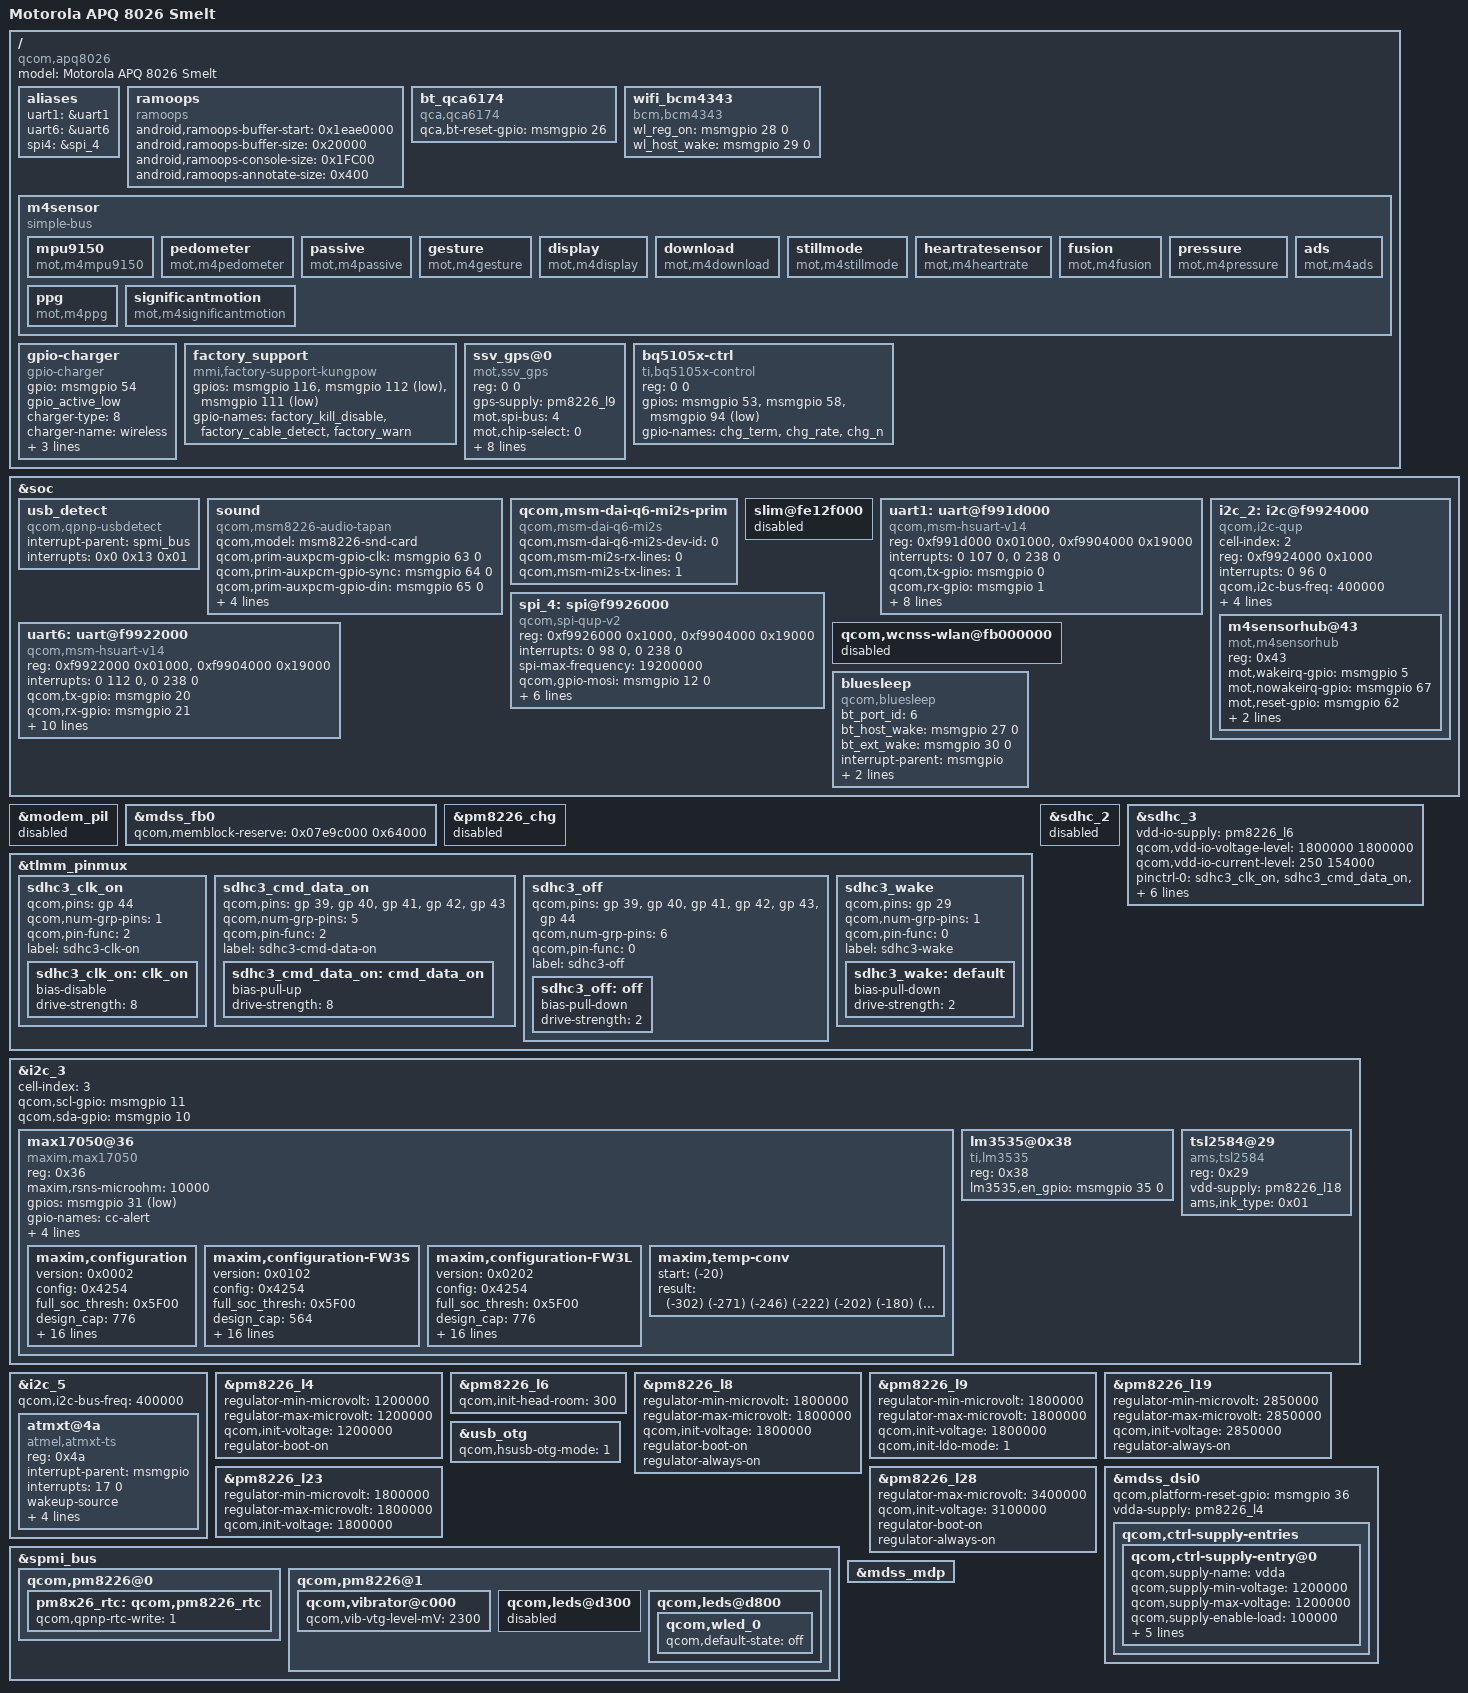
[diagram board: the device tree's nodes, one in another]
/* Copyright (c) 2014, The Linux Foundation. All rights reserved.
 *
 * This program is free software; you can redistribute it and/or modify
 * it under the terms of the GNU General Public License version 2 and
 * only version 2 as published by the Free Software Foundation.
 *
 * This program is distributed in the hope that it will be useful,
 * but WITHOUT ANY WARRANTY; without even the implied warranty of
 * MERCHANTABILITY or FITNESS FOR A PARTICULAR PURPOSE.  See the
 * GNU General Public License for more details.
 */

/memreserve/ 0x1eae0000 0x20000;

#include "qcom/apq8026-v2.dtsi"
#include "qcom/msm8226-w-memory.dtsi"
#include "qcom/msm8226-w-qseecom.dtsi"
#include "qcom/msm8226-w-sharedmem.dtsi"
#include "qcom/msm8226-720p-mtp.dtsi"
#include "apq8026-smelt-gpiomux.dtsi"

/ {
	model = "Motorola APQ 8026 Smelt";
	compatible = "qcom,apq8026", "qcom,msm8226", "qcom,mtp", "moto,smelt";

	aliases {
		/delete-property/ spi0;
		uart1 = &uart1;
		uart6 = &uart6;
		spi4 = &spi_4;
	};

	ramoops {
		compatible = "ramoops";
		status = "ok";

		android,ramoops-buffer-start = <0x1eae0000>;
		android,ramoops-buffer-size  = <0x20000>;
		android,ramoops-console-size = <0x1FC00>;
		android,ramoops-annotate-size = <0x400>;
	};

	bt_qca6174 {
		compatible = "qca,qca6174";
		qca,bt-reset-gpio = <&msmgpio 26 0>; /* BT_ENABLE */
	};

	wifi_bcm4343 {
		compatible = "bcm,bcm4343";
		wl_reg_on = <&msmgpio 28 0>;
		wl_host_wake = <&msmgpio 29 0>;
		status = "ok";
	};

	m4sensor {
		compatible = "simple-bus";

		mpu9150 {
			compatible = "mot,m4mpu9150";
		};
		pedometer {
			compatible = "mot,m4pedometer";
		};
		passive {
			compatible = "mot,m4passive";
		};
		gesture {
			compatible = "mot,m4gesture";
		};

		display {
			compatible = "mot,m4display";
		};
		download {
			compatible = "mot,m4download";
		};
		stillmode {
			compatible = "mot,m4stillmode";
		};

		heartratesensor {
			compatible = "mot,m4heartrate";
		};
		fusion {
			compatible = "mot,m4fusion";
		};
		pressure {
			compatible = "mot,m4pressure";
		};
		ads {
			compatible = "mot,m4ads";
		};
		ppg {
			compatible = "mot,m4ppg";
		};
		significantmotion {
			compatible = "mot,m4significantmotion";
		};
	};

	gpio-charger {
		compatible = "gpio-charger";
		gpio = <&msmgpio 54 0>;
		gpio_active_low;
		charger-type = <8>; /* POWER_SUPPLY_TYPE_WIRELESS */
		charger-name = "wireless";
		supplied_to = "max170xx_battery";
		switch-name = "dock";
		wakeup;
	};

	factory_support {
		compatible = "mmi,factory-support-kungpow";
		gpios = <&msmgpio 116 0x0>, /* GPIOF_OUT_INIT_LOW */
			<&msmgpio 112 0x1>, /* GPIOF_IN */
			<&msmgpio 111 0x1>; /* GPIOF_IN */
		gpio-names = "factory_kill_disable",
			     "factory_cable_detect",
			     "factory_warn";
	};

	ssv_gps@0 {
		compatible = "mot,ssv_gps";
		status = "ok";
		reg = <0 0>;
		gps-supply = <&pm8226_l9>;

		mot,spi-bus = <4>;
		mot,chip-select = <0>;
		mot,gps-spi-max-frequency = <6800000>;
		mot,rtc-clk = "sleep_clk";
		mot,modalias = "spidev";

		mot,boot-select-gpio = <&msmgpio 34 0x00>;
		mot,on-off-gpio      = <&msmgpio 37 0x00>;
		mot,irq-gpio         = <&msmgpio 46 0x00>;
		mot,reset-gpio       = <&msmgpio 48 0x00>;
		mot,host-wakeup-gpio = <&msmgpio 72 0x00>;
	};
	bq5105x-ctrl {
		reg = <0 0>;
		compatible = "ti,bq5105x-control";
		gpios = <&msmgpio 53 0x0>, /* WCHG_TERMINATE, GPIOF_OUT_INIT_LOW */
			<&msmgpio 58 0x0>, /* CHARGE_RATE, GPIOF_OUT_INIT_LOW */
		        <&msmgpio 94 0x1>; /* CHARGER_STARTB_1P8_N, GPIOF_IN */
		gpio-names = "chg_term",
			     "chg_rate",
			     "chg_n";
	};
};

&soc {
	usb_detect {
		compatible = "qcom,qpnp-usbdetect";
		interrupt-parent = <&spmi_bus>;
		interrupts = <0x0 0x13 0x01>;
		interrupt-names = "vbus_det_irq";
	};

	sound {
		compatible = "qcom,msm8226-audio-tapan";
		qcom,model = "msm8226-snd-card";
		qcom,prim-auxpcm-gpio-clk  = <&msmgpio 63 0>;
		qcom,prim-auxpcm-gpio-sync = <&msmgpio 64 0>;
		qcom,prim-auxpcm-gpio-din  = <&msmgpio 65 0>;
		qcom,prim-auxpcm-gpio-dout = <&msmgpio 66 0>;
		qcom,prim-auxpcm-gpio-set = "prim-gpio-prim";
		qcom,no-codec;
		qcom,mic-power-supply = <&pm8226_l23>;

		/delete-property/ qcom,audio-routing;
		/delete-property/ qcom,cdc-mclk-gpios;
		/delete-property/ qcom,cdc-vdd-spkr-gpios;
		/delete-property/ qcom,cdc-us-euro-gpios;
	};

	qcom,msm-dai-q6-mi2s-prim {
		compatible = "qcom,msm-dai-q6-mi2s";
		qcom,msm-dai-q6-mi2s-dev-id = <0>;
		qcom,msm-mi2s-rx-lines = <0>;
		qcom,msm-mi2s-tx-lines = <1>;
	};

	slim@fe12f000 {
		status = "disabled";
	};
	/delete-node/ sound-9302;

	/* BLSP1: UART */
	/delete-node/ spi@f9923000;
	uart1: uart@f991d000 { /* BLSP1 UART1 */
		compatible = "qcom,msm-hsuart-v14";
		reg = <0xf991d000 0x01000>,
		      <0xf9904000 0x19000>;
		reg-names = "core_mem", "bam_mem";
		interrupts = <0 107 0>, <0 238 0>;
		interrupt-names = "core_irq", "bam_irq";

		qcom,tx-gpio = <&msmgpio 0 0x00>;
		qcom,rx-gpio = <&msmgpio 1 0x00>;

		qcom,bam-tx-ep-pipe-index = <0>; /* BAM Consumer Pipe */
		qcom,bam-rx-ep-pipe-index = <1>; /* BAM Producer Pipe */
		qcom,msm-bus,name = "uart1";
		qcom,msm-bus,num-cases = <2>;
		qcom,msm-bus,num-paths = <1>;
		qcom,msm-obs;

		qcom,msm-bus,vectors-KBps =
			<86 512 0 0>,
			<86 512 500 800>;
	};

	/* BLSP2: I2C */
	i2c_2: i2c@f9924000 { /* BLSP-1 QUP-2 */
		cell-index = <2>;
		compatible = "qcom,i2c-qup";
		reg = <0xf9924000 0x1000>;
		#address-cells = <1>;
		#size-cells = <0>;
		reg-names = "qup_phys_addr";
		interrupts = <0 96 0>;
		interrupt-names = "qup_err_intr";
		qcom,i2c-bus-freq = <400000>;
		qcom,i2c-src-freq = <19200000>;
		qcom,scl-gpio = <&msmgpio 6 0>;
		qcom,sda-gpio = <&msmgpio 7 0>;
		qcom,master-id = <86>;
	};

	/* BLSP1-QUP3: [spi_4] (GPS) */
	/delete-node/ i2c@f9926000;
	spi_4: spi@f9926000 { /* BLSP1-QUP3 SPI4 */
		compatible = "qcom,spi-qup-v2";
		#address-cells = <1>;
		#size-cells = <0>;
		reg-names = "spi_physical", "spi_bam_physical";
		reg = <0xf9926000 0x1000>,
			<0xf9904000 0x19000>;
		interrupt-names = "spi_irq", "spi_bam_irq";
		interrupts = <0 98 0>, <0 238 0>;
		spi-max-frequency = <19200000>;
		qcom,gpio-mosi = <&msmgpio 12 0>;
		qcom,gpio-miso = <&msmgpio 13 0>;
		qcom,gpio-clk  = <&msmgpio 15 0>;
		qcom,gpio-cs0  = <&msmgpio 14 0>;
		qcom,infinite-mode = <0>;
		qcom,ver-reg-exists;
		qcom,master-id = <86>;
	};

	/* BLSP6: [uart] BT */
	uart6: uart@f9922000 { /* BLSP1 UART6 */
		compatible = "qcom,msm-hsuart-v14";
		reg = <0xf9922000 0x01000>,
		      <0xf9904000 0x19000>;
		reg-names = "core_mem", "bam_mem";
		interrupts = <0 112 0>, <0 238 0>;
		interrupt-names = "core_irq", "bam_irq";

		qcom,tx-gpio = <&msmgpio 20 0x00>;
		qcom,rx-gpio = <&msmgpio 21 0x00>;
		qcom,cts-gpio = <&msmgpio 22 0x00>;
		qcom,rfr-gpio = <&msmgpio 23 0x00>;

		qcom,bam-tx-ep-pipe-index = <10>; /* BAM Consumer Pipe */
		qcom,bam-rx-ep-pipe-index = <11>; /* BAM Producer Pipe */
		qcom,msm-bus,name = "uart6";
		qcom,msm-bus,num-cases = <2>;
		qcom,msm-bus,num-paths = <1>;
		qcom,msm-obs;

		qcom,msm-bus,vectors-KBps =
			<86 512 0 0>,
			<86 512 500 800>;
	};

	qcom,wcnss-wlan@fb000000 {
		status = "disabled";
	};

	bluesleep {
		compatible = "qcom,bluesleep";
		bt_port_id = <6>;
		bt_host_wake = <&msmgpio 27 0>;
		bt_ext_wake = <&msmgpio 30 0>;
		interrupt-parent = <&msmgpio>;
		interrupts = <27 0>;
		interrupt-names = "host_wake";
		tx-timer-interval = <1>;
	};

};

&modem_pil {
	status = "disabled";
	/delete-property/ linux,contiguous-region;
};

&mdss_fb0 {
	/* cont_splash memory*/
	qcom,memblock-reserve = <0x07e9c000 0x64000>;
};

&pm8226_chg {
	status = "disabled";
};

&tlmm_pinmux {
	sdhc3_clk_on {
		qcom,pins = <&gp 44>;
		qcom,num-grp-pins = <1>;
		qcom,pin-func = <2>;
		label = "sdhc3-clk-on";
		sdhc3_clk_on: clk_on {
			bias-disable;
			drive-strength = <8>;
		};
	};

	sdhc3_cmd_data_on {
		qcom,pins = <&gp 39 &gp 40 &gp 41 &gp 42 &gp 43>;
		qcom,num-grp-pins = <5>;
		qcom,pin-func = <2>;
		label = "sdhc3-cmd-data-on";
		sdhc3_cmd_data_on: cmd_data_on {
			bias-pull-up;
			drive-strength = <8>;
		};
	};

	sdhc3_off {
		qcom,pins = <&gp 39 &gp 40 &gp 41 &gp 42 &gp 43 &gp 44>;
		qcom,num-grp-pins = <6>;
		qcom,pin-func = <0>;
		label = "sdhc3-off";
		sdhc3_off: off {
			bias-pull-down;
			drive-strength = <2>;
		};
	};

	sdhc3_wake {
		qcom,pins = <&gp 29>;
		qcom,num-grp-pins = <1>;
		qcom,pin-func = <0>;
		label = "sdhc3-wake";
		sdhc3_wake: default {
			bias-pull-down;
			drive-strength = <2>;
		};
	};
};

&sdhc_2 {
	status = "disabled";
};

&sdhc_3 {
	vdd-io-supply = <&pm8226_l6>;
	qcom,vdd-io-voltage-level = <1800000 1800000>;
	qcom,vdd-io-current-level = <250 154000>;

	pinctrl-names = "active", "sleep";
	pinctrl-0 = <&sdhc3_clk_on &sdhc3_cmd_data_on &sdhc3_wake>;
	pinctrl-1 = <&sdhc3_off &sdhc3_wake>;

	interrupt-map = <0 &intc 0 127 0
			 1 &intc 0 224 0>;
	interrupt-names = "hc_irq", "pwr_irq";

	qcom,nonremovable;
	qcom,ignore_voltage_mismatch;
	qcom,no-uhs;
	status = "ok";
};

&i2c_2 {
	status = "ok";
		m4sensorhub@43 {
		compatible = "mot,m4sensorhub";
		status = "ok";

		reg = <0x43>;
		mot,wakeirq-gpio    = <&msmgpio 5 0x00>;
		mot,nowakeirq-gpio  = <&msmgpio 67 0x00>;
		mot,reset-gpio  = <&msmgpio 62 0x00>;
		mot,boot0-gpio  = <&msmgpio 109 0x00>;
		mot,fw-filename = "m4sensorhub-p0_dali.bin";
	};
};

&i2c_3 {
	cell-index = <3>;
	qcom,scl-gpio = <&msmgpio 11 0>;
	qcom,sda-gpio = <&msmgpio 10 0>;
	status = "ok";

	max17050@36 {
		compatible = "maxim,max17050";
		reg = <0x36>;
		maxim,rsns-microohm = <10000>;

		gpios = <&msmgpio 31 0x11>; /* CC_ALERT_N, GPIOF_DIR_IN | GPIOF_EXPORT */
		gpio-names = "cc-alert";
		interrupt-parent = <&msmgpio>;
		interrupts = <31 0>;  /* TBD? */

		/* These registers are set on every poweup */
		maxim,regs-init-data = <
			0x01 0xFF00 /* Valrt Threshold, IRQ disabled */
			0x02 0x7F80 /* Talrt Threshold, IRQ disabled */
		>;

		maxim,enable_por_init;

		/*
		 * /maxim,configuration is used when batt-id is not defined in /chosen,
		 * otherwise maxim,configuration-<batt_id> is used. Use LSB of the
		 * version property as a version number and MSB to identify battery.
		 * Incrementing version number forces re-programming of config data.
		 */
		maxim,configuration { /* Default to FW3L battery */
			/* Required properties */
			version		= /bits/ 16 <0x0002>;   /* MSB = 0x00, LSB is version */
			config		= /bits/ 16 <0x4254>;	/* TS = Tex = 0, Ss = Aen = Ten = ETHRM = 1 */
			full_soc_thresh	= /bits/ 16 <0x5F00>;	/* app note constant */
			design_cap	= /bits/ 16 <776>;	/* in 5uVh/Rsns = 0.5 mAh */
			ichgt_term	= /bits/ 16 <0x0080>;	/* battery attribute */
			learn_cfg	= /bits/ 16 <0x2606>;	/* app note constant */
			filter_cfg	= /bits/ 16 <0x87A4>;	/* app note constant */
			relax_cfg	= /bits/ 16 <0x043B>;	/* Load = 5 mA, dV = 3.7 mV, dT = 6 mins */
			fullcap		= /bits/ 16 <776>;	/* in 5uVh/Rsns = 0.5 mAh */
			fullcapnom	= /bits/ 16 <776>;	/* in 5uVh/Rsns = 0.5 mAh */
			qrtbl00		= /bits/ 16 <0x2f80>;	/* battery attribute */
			qrtbl10		= /bits/ 16 <0x1500>;	/* battery attribute */
			qrtbl20		= /bits/ 16 <0x0783>;	/* battery attribute */
			qrtbl30		= /bits/ 16 <0x0507>;	/* battery attribute */
			rcomp0 		= /bits/ 16 <0x0070>;	/* battery attribute */
			tcompc0		= /bits/ 16 <0x5040>;	/* battery attribute */
			maxim,cell-char-tbl = /bits/ 16 <	/* battery attribute */
				0x7d00 0xac70 0xb760 0xb940 0xba50 0xbca0
				0xbde0 0xc020 0xc190 0xc320 0xc6b0 0xcac0
				0xce60 0xd0d0 0xd5b0 0xdba0 0x0020 0x0300
				0x1100 0x0ce0 0x0fe0 0x1490 0x11d0 0x0c90
				0x0df0 0x0970 0x0600 0x08d0 0x0690 0x06f0
				0x05f0 0x05f0 0x0080 0x0080 0x0080 0x0080
				0x0080 0x0080 0x0080 0x0080 0x0080 0x0080
				0x0080 0x0080 0x0080 0x0080 0x0080 0x0080
			>;
			/* Optional properties */
			tgain		= /bits/ 16 <0xE71C>;	/* thermistor attribute */
			toff		= /bits/ 16 <0x251A>;	/* thermistor attribute */
		};

		maxim,configuration-FW3S {
			/* Required properties */
			version		= /bits/ 16 <0x0102>;   /* MSB = 0x01, LSB is version */
			config		= /bits/ 16 <0x4254>;	/* TS = Tex = 0, Ss = Aen = Ten = ETHRM = 1 */
			full_soc_thresh	= /bits/ 16 <0x5F00>;	/* app note constant */
			design_cap	= /bits/ 16 <564>;	/* in 5uVh/Rsns = 0.5 mAh */
			ichgt_term	= /bits/ 16 <0x0080>;	/* battery attribute */
			learn_cfg	= /bits/ 16 <0x2606>;	/* app note constant */
			filter_cfg	= /bits/ 16 <0x87A4>;	/* app note constant */
			relax_cfg	= /bits/ 16 <0x043B>;	/* Load = 5 mA, dV = 3.7 mV, dT = 6 mins */
			fullcap		= /bits/ 16 <564>;	/* in 5uVh/Rsns = 0.5 mAh */
			fullcapnom	= /bits/ 16 <564>;	/* in 5uVh/Rsns = 0.5 mAh */
			qrtbl00		= /bits/ 16 <0x3480>;	/* battery attribute */
			qrtbl10		= /bits/ 16 <0x1900>;	/* battery attribute */
			qrtbl20		= /bits/ 16 <0x0b09>;	/* battery attribute */
			qrtbl30		= /bits/ 16 <0x078b>;	/* battery attribute */
			rcomp0 		= /bits/ 16 <0x0038>;	/* battery attribute */
			tcompc0		= /bits/ 16 <0x1e2e>;	/* battery attribute */
			maxim,cell-char-tbl = /bits/ 16 <	/* battery attribute */
				0x80c0 0x9d60 0xb740 0xba80 0xbbb0 0xbc90
				0xbe00 0xbf60 0xc030 0xc2a0 0xc470 0xca00
				0xd010 0xd1b0 0xd580 0xdb10 0x0040 0x0110
				0x11c0 0x08f0 0x11d0 0x1310 0x1030 0x13f0
				0x0ca0 0x0df0 0x0760 0x06f0 0x06a0 0x07e0
				0x05f0 0x05f0 0x0100 0x0100 0x0100 0x0100
				0x0100 0x0100 0x0100 0x0100 0x0100 0x0100
				0x0100 0x0100 0x0100 0x0100 0x0100 0x0100
			>;
			/* Optional properties */
			tgain		= /bits/ 16 <0xE71C>;	/* thermistor attribute */
			toff		= /bits/ 16 <0x251A>;	/* thermistor attribute */
		};

		maxim,configuration-FW3L {
			/* Required properties */
			version		= /bits/ 16 <0x0202>;   /* MSB = 0x02, LSB is version */
			config		= /bits/ 16 <0x4254>;	/* TS = Tex = 0, Ss = Aen = Ten = ETHRM = 1 */
			full_soc_thresh	= /bits/ 16 <0x5F00>;	/* app note constant */
			design_cap	= /bits/ 16 <776>;	/* in 5uVh/Rsns = 0.5 mAh */
			ichgt_term	= /bits/ 16 <0x0080>;	/* battery attribute */
			learn_cfg	= /bits/ 16 <0x2606>;	/* app note constant */
			filter_cfg	= /bits/ 16 <0x87A4>;	/* app note constant */
			relax_cfg	= /bits/ 16 <0x043B>;	/* Load = 5 mA, dV = 3.7 mV, dT = 6 mins */
			fullcap		= /bits/ 16 <776>;	/* in 5uVh/Rsns = 0.5 mAh */
			fullcapnom	= /bits/ 16 <776>;	/* in 5uVh/Rsns = 0.5 mAh */
			qrtbl00		= /bits/ 16 <0x2f80>;	/* battery attribute */
			qrtbl10		= /bits/ 16 <0x1500>;	/* battery attribute */
			qrtbl20		= /bits/ 16 <0x0783>;	/* battery attribute */
			qrtbl30		= /bits/ 16 <0x0507>;	/* battery attribute */
			rcomp0 		= /bits/ 16 <0x0070>;	/* battery attribute */
			tcompc0		= /bits/ 16 <0x5040>;	/* battery attribute */
			maxim,cell-char-tbl = /bits/ 16 <	/* battery attribute */
				0x7d00 0xac70 0xb760 0xb940 0xba50 0xbca0
				0xbde0 0xc020 0xc190 0xc320 0xc6b0 0xcac0
				0xce60 0xd0d0 0xd5b0 0xdba0 0x0020 0x0300
				0x1100 0x0ce0 0x0fe0 0x1490 0x11d0 0x0c90
				0x0df0 0x0970 0x0600 0x08d0 0x0690 0x06f0
				0x05f0 0x05f0 0x0080 0x0080 0x0080 0x0080
				0x0080 0x0080 0x0080 0x0080 0x0080 0x0080
				0x0080 0x0080 0x0080 0x0080 0x0080 0x0080
			>;
			/* Optional properties */
			tgain		= /bits/ 16 <0xE71C>;	/* thermistor attribute */
			toff		= /bits/ 16 <0x251A>;	/* thermistor attribute */
		};

		maxim,temp-conv {
			start	= /bits/ 16 <(-20)>;	/* in degrees C */
			result	= /bits/ 16 <
				/* 1/10th C "real" temps corresponding start, start + 1, etc. fuel gauge temps in C */
				(-302) (-271) (-246) (-222) (-202) (-180) (-162) (-147) (-129) (-114)	/* -20 C ... -11 C */
				(-101) (-86)  (-72)  (-59)  (-48)  (-35)  (-23)  (-12)  (-2)   10	/* -10 C ... -1  C */
				22     32     42     51     62     72     82     91     99     110	/*  0  C ...  9  C */
				120    129    138    146    156    165    175    184    192    200	/*  10 C ...  19 C */
				210    220    230    238    247    256    266    275    285    294	/*  20 C ...  29 C */
				303    313    324    333    343    353    364    375    385    395	/*  30 C ...  39 C */
				407    419    430    441    453    466    479    492    505    520	/*  40 C ...  49 C */
				534    548    565    581    597    616    635    654    676    697	/*  50 C ...  59 C */
				721    747    775    800						/*  60 C ...  63 C */
			>;
		};
	};

	lm3535@0x38 {
		compatible = "ti,lm3535";
		reg = <0x38>;
		lm3535,en_gpio = <&msmgpio 35 0>; // is not supported by driver yet
	};

	tsl2584@29 {
		compatible = "ams,tsl2584";
		reg = <0x29>;
		vdd-supply = <&pm8226_l18>;
		ams,ink_type = <0x01>;
	};

};

&i2c_5 {
	status = "ok";
	qcom,i2c-bus-freq = <400000>;
	/* drivers here */
	atmxt@4a {
		compatible = "atmel,atmxt-ts";
		reg = <0x4a>;
		interrupt-parent = <&msmgpio>;
		interrupts = <17 0>;
		wakeup-source;
		gpios = <&msmgpio 17 0>, /* IRQ */
			<&msmgpio 16 0>; /* RESET */
		touch_vdd-supply = <&pm8226_l28>;
		atmel,atmxt-tdat-filename = "atmxt-r3.tdat";
		atmel,enable_at_boot = <0x00>;
	};
};

&pm8226_l4 {
	regulator-min-microvolt = <1200000>;
	regulator-max-microvolt = <1200000>;
	qcom,init-voltage = <1200000>;
	regulator-boot-on;
};

&pm8226_l6 {
	qcom,init-head-room = <300>;
};

&pm8226_l8 {
	regulator-min-microvolt = <1800000>;
	regulator-max-microvolt = <1800000>;
	qcom,init-voltage = <1800000>;
	regulator-boot-on;
	regulator-always-on;
};

&pm8226_l9 {
	regulator-min-microvolt = <1800000>;
	regulator-max-microvolt = <1800000>;
	qcom,init-voltage = <1800000>;
	qcom,init-ldo-mode = <1>;
};

&pm8226_l19 {
	regulator-min-microvolt = <2850000>;
	regulator-max-microvolt = <2850000>;
	qcom,init-voltage = <2850000>;
	regulator-always-on;
};

&pm8226_l23 {
	regulator-min-microvolt = <1800000>;
	regulator-max-microvolt = <1800000>;
	qcom,init-voltage = <1800000>;
};

&pm8226_l28 {
	regulator-max-microvolt = <3400000>;
	qcom,init-voltage = <3100000>;
	regulator-boot-on;
	regulator-always-on;
};

&spi_4 {
	status = "ok";
};

&uart1 {
	status = "ok";
};

&uart6 {
	status = "ok";
};

&usb_otg {
	qcom,hsusb-otg-mode = <1>;         /* USB_PERIPHERAL           */
};

&mdss_dsi0 {
	qcom,platform-reset-gpio = <&msmgpio 36 0>;
	vdda-supply = <&pm8226_l4>;
	/delete-node/ qcom,ctrl-supply-entries;
	/delete-node/ qcom,panel-supply-entries;
	qcom,ctrl-supply-entries {
		qcom,ctrl-supply-entry@0 {
			qcom,supply-name = "vdda";
			qcom,supply-min-voltage = <1200000>;
			qcom,supply-max-voltage = <1200000>;
			qcom,supply-enable-load = <100000>;
			qcom,supply-disable-load = <100>;
			qcom,supply-pre-on-sleep = <0>;
			qcom,supply-post-on-sleep = <2>;
			qcom,supply-pre-off-sleep = <0>;
			qcom,supply-post-off-sleep = <0>;
		};
	};
};

&spmi_bus {
	qcom,pm8226@0 {
		pm8x26_rtc: qcom,pm8226_rtc {
			qcom,qpnp-rtc-write = <1>;
		};
	};
        qcom,pm8226@1 {
		qcom,vibrator@c000 {
			qcom,vib-vtg-level-mV = <2300>;
		};
		qcom,leds@d300 {
			status = "disabled";
		};
		qcom,leds@d800 {
			qcom,wled_0 {
				qcom,default-state = "off";
			};
		};
	};
};

/* remove unsupported panels */
&mdss_mdp {
	/delete-node/ qcom,mdss_dsi_hx8394a_720p_video;
	/delete-node/ qcom,mdss_dsi_nt35590_720p_video;
	/delete-node/ qcom,mdss_dsi_nt35521_720p_video;
	/delete-node/ qcom,mdss_dsi_nt35596_1080p_video;
	/delete-node/ qcom,mdss_dsi_nt35590_720p_cmd;
	/delete-node/ qcom,mdss_dsi_ssd2080m_720p_video;
	/delete-node/ qcom,mdss_dsi_jdi_1080p_video;
	/delete-node/ qcom,mdss_dsi_nt35590_qvga_cmd;
};
